# BE-U1000 register map
Vendor: BAIKAL ELECTRONICS, JSC; File version: 1.0
CPU: RISC-V r0p0, little endian, no MPU, no FPU, 3 interrupt priority bits
Registers are 32-bit, read-write, reset 0x0 unless marked. A register's access mark holds for its fields unless they carry their own. Offsets are from the block's base; [hi:lo] are bit positions; {n}, {i} and the like mark numbered series.

## QE0 — Quadrature Encoder
Base 0x14004050
Same registers: QE1 0x14005050, QE2 0x14006050, QE3 0x14007050
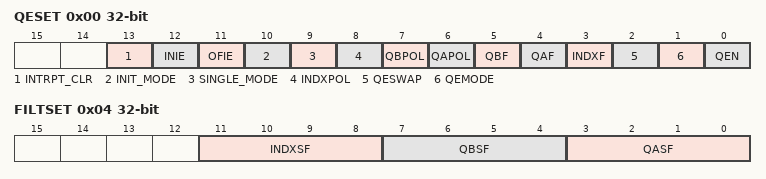
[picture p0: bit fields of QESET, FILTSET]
0x00 QESET — Control register
  [13] INTRPT_CLR — Interrupt clear
    0=DISABLE; 1=ENABLE
  [12] INIE — INDX interrupt enable
    0=DISABLE; 1=ENABLE
  [11] OFIE — Overflow interrupt enable
    0=DISABLE; 1=ENABLE
  [10] INIT_MODE — Counter initialization mode
    0=RESET (INDX resets the counter); 1=INITSET (INDX sets the counter to INITSET value)
  [9] SINGLE_MODE — Single mode enable
    0=DISABLE (Single mode is disabled); 1=ENABLE (Single mode is enabled)
  [8] INDXPOL — INDX polarity
    0=NONINVERTED (INDX signal is not inverted); 1=INVERTED (INDX signal is inverted)
  [7] QBPOL — QB polarity
    0=NONINVERTED (QB signal is not inverted); 1=INVERTED (QB signal is inverted)
  [6] QAPOL — QA polarity
    0=NONINVERTED (QA signal is not inverted); 1=INVERTED (QA signal is inverted)
  [5] QBF — QB filtering enable
    0=DISABLE; 1=ENABLE
  [4] QAF — QA filtering enable
    0=DISABLE; 1=ENABLE
  [3] INDXF — INDX filtering enable
    0=DISABLE; 1=ENABLE
  [2] QESWAP — QA swapped with QB
    0=DISABLE; 1=ENABLE
  [1] QEMODE — Counting mode
    0=QUADRATURE (Counter counts up/down on both QA and QB edges depending on the level of the other input); 1=EDGE (Counter counts up/down on QA edge depending on QB level)
  [0] QEN — Encoder enable
    0=DISABLE; 1=ENABLE
0x04 FILTSET — Filters setting register
  [all] fields
    0=FDIV1 (No filter, sampling is done at fDTS); 1=FDIV1_N2 (fSAMPLING = fCK_INT, N = 2); 2=FDIV1_N4 (fSAMPLING = fCK_INT, N = 4); 3=FDIV1_N8 (fSAMPLING = fCK_INT, N = 8); 4=FDIV2_N6 (fSAMPLING = fDTS/2, N = 6); 5=FDIV2_N8 (fSAMPLING = fDTS/2, N = 8); 6=FDIV4_N6 (fSAMPLING = fDTS/4, N = 6); 7=FDIV4_N8 (fSAMPLING = fDTS/4, N = 8); 8=FDIV8_N6 (fSAMPLING = fDTS/8, N = 6); 9=FDIV8_N8 (fSAMPLING = fDTS/8, N = 8); 10=FDIV16_N5 (fSAMPLING = fDTS/16, N = 5); 11=FDIV16_N6 (fSAMPLING = fDTS/16, N = 6); 12=FDIV16_N8 (fSAMPLING = fDTS/16, N = 8); 13=FDIV32_N5 (fSAMPLING = fDTS/32, N = 5); 14=FDIV32_N6 (fSAMPLING = fDTS/32, N = 6); 15=FDIV32_N8 (fSAMPLING = fDTS/32, N = 8)
  [11:8] INDXSF — INDX filter setting
  [7:4] QBSF — QB filter setting
  [3:0] QASF — QA filter setting
0x08 QEMAX — Max counter value register
  [15:0] QEMAX
0x0C INITSET — Init counter value register
  [15:0] INITSET
0x10 QECNT — Current counter value register
  [15:0] QECNT

## TIM0 — Timer
Base 0x11007000
Same registers: TIM1 0x13007000
0x00 CH_LOADCOUNT10 — Channel 0 Load Count Register
  [31:0] CH_LOADCOUNT1 — The value to be loaded into timer channel n
{0x4+0x14*i} CH_CURRENTVAL{i} (i=0..3) — Channel {i} Current Value Register
  [31:0] CH_CURRENTVAL — Current value of timer channel n
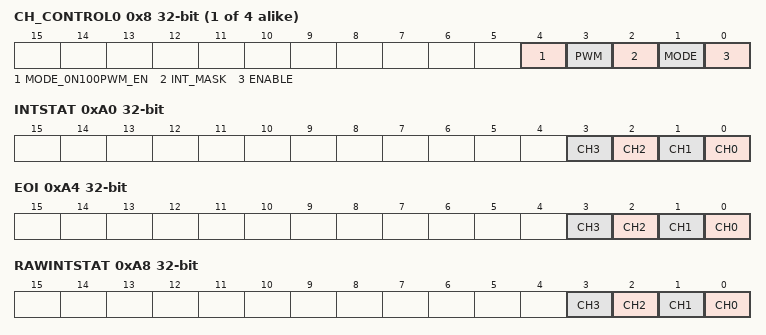
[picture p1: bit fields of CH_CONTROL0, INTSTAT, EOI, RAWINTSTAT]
{0x8+0x14*i} CH_CONTROL{i} (i=0..3) — Channel {i} Control Register
  [4] MODE_0N100PWM_EN — Timer channel n 0% and 100% PWM duty cycle mode enable
    0=DISABLE; 1=ENABLE
  [3] PWM — Timer channel n PWM output enable
    0=DISABLE; 1=ENABLE
  [2] INT_MASK — Timer channel n interrupt mask
    0=DISABLE; 1=ENABLE
  [1] MODE — Timer channel n mode
    0=FREE_RUNNING (Free Running mode); 1=USER_DEFINED (User Defined mode)
  [0] ENABLE — Timer channel n enable
    0=DISABLE; 1=ENABLE
{0xC+0x14*i} CH_EOI{i} (i=0..3) — Channel {i} End-of-Interrupt Register
  [0] CH_EOI — Clear timer channel n interrupt
    0=DISABLE; 1=ENABLE
{0x10+0x14*i} CH_INTSTAT{i} (i=0..3) — Channel {i} Interrupt Status Register
  [0] CH_INTSTAT — Timer channel n interrupt status
    0=DISABLE; 1=ENABLE
0x14 CH_LOADCOUNT11 — Channel 1 Load Count Register
  [31:0] CH_LOADCOUNT1 — The value to be loaded into timer channel n
0x28 CH_LOADCOUNT12 — Channel 2 Load Count Register
  [31:0] CH_LOADCOUNT1 — The value to be loaded into timer channel n
0x3C CH_LOADCOUNT13 — Channel 3 Load Count Register
  [31:0] CH_LOADCOUNT1 — The value to be loaded into timer channel n
0xA0 INTSTAT — Interrupt Status Register
  [all] fields
    0=DISABLE; 1=ENABLE
  [n] CH{n} (n=0..3) — Timer channel {n} interrupt status
0xA4 EOI — End-of-Interrupt Register
  [all] fields
    0=DISABLE; 1=ENABLE
  [n] CH{n} (n=0..3) — Clear timer channel {n} interrupt
0xA8 RAWINTSTAT — Raw Interrupt Status Register
  [all] fields
    0=DISABLE; 1=ENABLE
  [n] CH{n} (n=0..3) — Timer channel {n} unmasked interrupt status
0xAC COMPVERSION — Component Version Register
  [31:0] COMPVERSION — Timer component version
{0x60+4i} CH_LOADCOUNT{i} (i=20..23) — Channel {i-20} Load Count2 Register
  [31:0] CH_LOADCOUNT2 — Value to be loaded into timer channel n when toggle output changes from 0 to 1

## WDT0 — WatchDog Timer (WDT)
Base 0x11008000
Same registers: WDT1 0x13008000
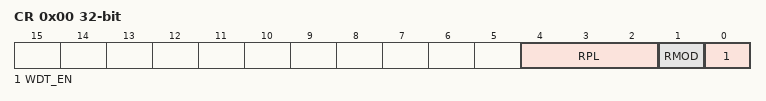
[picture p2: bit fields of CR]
0x00 CR — Control
  [4:2] RPL — Reset pulse length
    0=CYCLES_2 (2 clock cycles); 1=CYCLES_4 (4 clock cycles); 2=CYCLES_8 (8 clock cycles); 3=CYCLES_16 (16 clock cycles); 4=CYCLES_32 (32 clock cycles); 5=CYCLES_64 (64 clock cycles); 6=CYCLES_128 (128 clock cycles); 7=CYCLES_256 (256 clock cycles)
  [1] RMOD — Response mode
    0=RESET (Generate a system reset); 1=INTERRUPT (First generate an interrupt, then a system reset)
  [0] WDT_EN — Enable and disable the WDT
    0=DISABLED (Watchdog timer disabled); 1=ENABLED (Watchdog timer enabled)
0x04 TORR — Timeout Range
  [3:0] TOP — Timeout period
    0=USER_0 (0xFF cycles); 1=USER_1 (0x1FF cycles); 2=USER_2 (0x3FF cycles); 3=USER_3 (0x7FF cycles); 4=USER_4 (0xFFFF cycles); 5=USER_5 (0x1FFFF cycles); 6=USER_6 (0x3FFFF cycles); 7=USER_7 (0x7FFFF cycles); 8=USER_8 (0xFFFFF cycles); 9=USER_9 (0x1FFFFF cycles); 10=USER_10 (0x3FFFFF cycles); 11=USER_11 (0x7FFFFF cycles); 12=USER_12 (0xFFFFFF cycles); 13=USER_13 (0x1FFFFFF cycles); 14=USER_14 (0x3FFFFFF cycles); 15=USER_15 (0x7FFFFFF cycles)
0x08 CCVR — Current Counter Value
  [31:0] CCVR — WDT Current Counter Value Register
0x0C CRR — Counter Restart
  [7:0] CRR — Counter Restart Register
0x10 STAT — Interrupt Status
  [0] STAT — Interrupt status of the WDT
    0=WDT_STAT_INACTIVE (Interrupt is inactive); 1=WDT_STAT_ACTIVE (Interrupt is active regardless of polarity)
0x14 EOI — Interrupt Clear
  [0] EOI — Clears the watchdog interrupt
    0=DISABLE; 1=ENABLE

## CORE2_INT — CORE2 subsystem, INT
Base 0x151037F0
0x00 IER — Interrupt enable register
  [0] EN — CORE2 interrupt enable
    0=DISABLE; 1=ENABLE

## CORE2_PIO — CORE2 subsystem, PIO
Base 0x151037F4
0x00 IN — Input data register
0x04 EN — Direction control register
0x08 OU — Output data register

## CORE2_DEBUG — CORE2 subsystem, DEBUG
Base 0x11000000
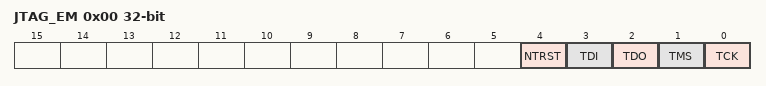
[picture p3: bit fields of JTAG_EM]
0x00 JTAG_EM — JTAG emulation register
  [all] fields
    0=DISABLE; 1=ENABLE
  [4] NTRST — NTRST signal propagated to PA4
  [3] TDI — TDI signal propagated to PA3
  [2] TDO — TDO signal on PA2
  [1] TMS — TMS signal propagated to PA1
  [0] TCK — TCK signal propagated to PA0

## CORE2_TRACE — CORE2 subsystem, TRACE
Base 0x11000000
0x00 TRACE_SEL — Trace select register
  [0] SEL — Alternative trace source select
    0=CORE0; 1=CORE1
